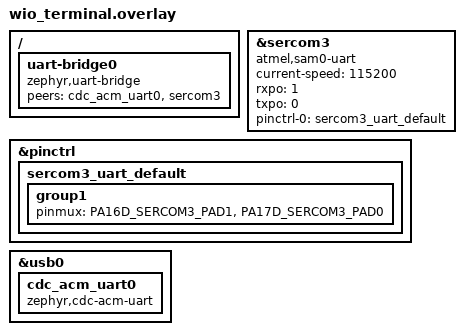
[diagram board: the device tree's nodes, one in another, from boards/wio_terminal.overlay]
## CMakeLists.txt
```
# SPDX-License-Identifier: Apache-2.0

cmake_minimum_required(VERSION 3.20.0)

find_package(Zephyr REQUIRED HINTS $ENV{ZEPHYR_BASE})
project(usb2uart)

include(${ZEPHYR_BASE}/samples/subsys/usb/common/common.cmake)

FILE(GLOB app_sources src/*.c)
target_sources(app PRIVATE ${app_sources})
```

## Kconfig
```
# SPDX-License-Identifier: Apache-2.0

# Source common USB sample options for sample_usbd_init
source "samples/subsys/usb/common/Kconfig.sample_usbd"

config USB2UART_DISPLAY_REFRESH_MS
	int "Display refresh interval in milliseconds"
	default 100
	help
	  How often the LVGL display refreshes status.

source "Kconfig.zephyr"
```

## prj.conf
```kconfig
# Console on board_cdc_acm_uart (kept for USB enumeration)
CONFIG_UART_CONSOLE=y
CONFIG_SHELL=y

# USB Device
CONFIG_USB_DEVICE_STACK_NEXT=y
CONFIG_USBD_CDC_ACM_CLASS=y
CONFIG_CDC_ACM_SERIAL_INITIALIZE_AT_BOOT=n

# Serial / UART
CONFIG_SERIAL=y
CONFIG_UART_INTERRUPT_DRIVEN=y
CONFIG_UART_LINE_CTRL=y
CONFIG_UART_USE_RUNTIME_CONFIGURE=y
CONFIG_UART_BRIDGE=y
CONFIG_UART_BRIDGE_BUF_SIZE=2048

# USB UDC buffers
CONFIG_UDC_BUF_COUNT=32
CONFIG_UDC_BUF_POOL_SIZE=4096

# Sample USBD options
CONFIG_SAMPLE_USBD_PID=0x0001
CONFIG_SAMPLE_USBD_PRODUCT="Wio Terminal USB2UART"

# Logging
CONFIG_LOG=y

# Main stack
CONFIG_MAIN_STACK_SIZE=4096

# Display
CONFIG_DISPLAY=y

# LVGL
CONFIG_LVGL=y
CONFIG_LV_Z_MEM_POOL_SIZE=16384
CONFIG_LV_USE_LABEL=y
CONFIG_LV_FONT_MONTSERRAT_10=y
CONFIG_LV_FONT_MONTSERRAT_14=y
CONFIG_LV_FONT_MONTSERRAT_38=y
CONFIG_LV_Z_VDB_SIZE=10

# Heap for LVGL
CONFIG_HEAP_MEM_POOL_SIZE=8192
```

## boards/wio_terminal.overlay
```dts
/*
 * Wio Terminal USB2UART overlay
 * SERCOM3 -> UART on left Grove (PA17=TX PAD0, PA16=RX PAD1)
 * USB CDC ACM <-> SERCOM3 uart bridge
 *
 * Keep board_cdc_acm_uart (console/shell), add cdc_acm_uart0 for bridge.
 * The device will enumerate as a composite USB device with two CDC ACM interfaces.
 */

/* Override SERCOM3 from I2C to UART */
&sercom3 {
	/delete-property/ compatible;
	/delete-property/ clock-frequency;
	/delete-property/ #address-cells;
	/delete-property/ #size-cells;
	compatible = "atmel,sam0-uart";
	status = "okay";
	current-speed = <115200>;
	rxpo = <1>;
	txpo = <0>;
	pinctrl-0 = <&sercom3_uart_default>;
	pinctrl-names = "default";
};

/* Add SERCOM3 UART pinctrl (PA17=SERCOM3_PAD0 TX, PA16=SERCOM3_PAD1 RX) */
&pinctrl {
	sercom3_uart_default: sercom3_uart_default {
		group1 {
			pinmux = <PA16D_SERCOM3_PAD1>,
				 <PA17D_SERCOM3_PAD0>;
		};
	};
};

/* Second CDC ACM UART instance under USB controller for bridge */
&usb0 {
	cdc_acm_uart0: cdc_acm_uart0 {
		compatible = "zephyr,cdc-acm-uart";
	};
};

/* UART Bridge: CDC ACM <-> SERCOM3 */
/ {
	uart-bridge0 {
		compatible = "zephyr,uart-bridge";
		peers = <&cdc_acm_uart0 &sercom3>;
	};
};
```

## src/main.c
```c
/*
 * SPDX-License-Identifier: Apache-2.0
 */

#include <zephyr/device.h>
#include <zephyr/drivers/uart/uart_bridge.h>
#include <zephyr/kernel.h>
#include <zephyr/usb/usb_device.h>
#include <zephyr/usb/usbd.h>

#include <sample_usbd.h>

#include "bridge_monitor.h"
#include "display.h"

#include <zephyr/logging/log.h>
LOG_MODULE_REGISTER(usb2uart, LOG_LEVEL_INF);

const struct device *const cdc_dev = DEVICE_DT_GET(DT_NODELABEL(cdc_acm_uart0));

static struct usbd_context *sample_usbd;
static bool usb_connected;

#define DEVICE_DT_GET_COMMA(node_id) DEVICE_DT_GET(node_id),

const struct device *uart_bridges[] = {
	DT_FOREACH_STATUS_OKAY(zephyr_uart_bridge, DEVICE_DT_GET_COMMA)
};

static void sample_msg_cb(struct usbd_context *const ctx, const struct usbd_msg *msg)
{
	LOG_INF("USBD message: %s", usbd_msg_type_string(msg->type));

	if (usbd_can_detect_vbus(ctx)) {
		if (msg->type == USBD_MSG_VBUS_READY) {
			usbd_enable(ctx);
		}
		if (msg->type == USBD_MSG_VBUS_REMOVED) {
			usbd_disable(ctx);
		}
	}

	if (msg->type == USBD_MSG_CDC_ACM_LINE_CODING ||
	    msg->type == USBD_MSG_CDC_ACM_CONTROL_LINE_STATE) {
		for (uint8_t i = 0; i < ARRAY_SIZE(uart_bridges); i++) {
			uart_bridge_settings_update(msg->dev, uart_bridges[i]);
		}
	}

	if (msg->type == USBD_MSG_CDC_ACM_CONTROL_LINE_STATE) {
		usb_connected = true;
	}
}

int main(void)
{
	int err;

	sample_usbd = sample_usbd_init_device(sample_msg_cb);
	if (sample_usbd == NULL) {
		LOG_ERR("Failed to initialize USB device");
		return -ENODEV;
	}

	if (!usbd_can_detect_vbus(sample_usbd)) {
		err = usbd_enable(sample_usbd);
		if (err) {
			LOG_ERR("Failed to enable device support");
			return err;
		}
	}

	bridge_monitor_init(cdc_dev, NULL);

	display_init();

	LOG_INF("USB2UART bridge ready");

	while (1) {
		struct uart_config_info cfg;

		bridge_monitor_get_config(&cfg);
		cfg.connected = usb_connected;
		display_update_status(cfg.baudrate, cfg.data_bits,
				     cfg.stop_bits, cfg.parity, cfg.connected);
		display_refresh();
		k_sleep(K_MSEC(CONFIG_USB2UART_DISPLAY_REFRESH_MS));
	}

	return 0;
}
```

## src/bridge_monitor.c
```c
/*
 * SPDX-License-Identifier: Apache-2.0
 */

#include "bridge_monitor.h"
#include <zephyr/drivers/uart.h>
#include <zephyr/logging/log.h>
LOG_MODULE_REGISTER(bridge_monitor, LOG_LEVEL_INF);

static const struct device *cdc_dev;

static struct uart_config_info current_cfg = {
	.baudrate = 115200,
	.data_bits = 8,
	.stop_bits = 1,
	.parity = 0,
	.connected = false,
};

void bridge_monitor_init(const struct device *cdc, const struct device *uart)
{
	ARG_UNUSED(uart);
	cdc_dev = cdc;
}

void bridge_monitor_get_config(struct uart_config_info *cfg)
{
	struct uart_config tmp;
	int ret;

	if (cdc_dev == NULL) {
		*cfg = current_cfg;
		return;
	}

	ret = uart_config_get(cdc_dev, &tmp);
	if (ret == 0) {
		current_cfg.baudrate = tmp.baudrate;
		switch (tmp.data_bits) {
		case UART_CFG_DATA_BITS_5:
			current_cfg.data_bits = 5;
			break;
		case UART_CFG_DATA_BITS_6:
			current_cfg.data_bits = 6;
			break;
		case UART_CFG_DATA_BITS_7:
			current_cfg.data_bits = 7;
			break;
		case UART_CFG_DATA_BITS_8:
			current_cfg.data_bits = 8;
			break;
		case UART_CFG_DATA_BITS_9:
			current_cfg.data_bits = 9;
			break;
		default:
			current_cfg.data_bits = 8;
			break;
		}
		switch (tmp.stop_bits) {
		case UART_CFG_STOP_BITS_0_5:
			current_cfg.stop_bits = 0;
			break;
		case UART_CFG_STOP_BITS_1:
			current_cfg.stop_bits = 1;
			break;
		case UART_CFG_STOP_BITS_1_5:
			current_cfg.stop_bits = 15;
			break;
		case UART_CFG_STOP_BITS_2:
			current_cfg.stop_bits = 2;
			break;
		default:
			current_cfg.stop_bits = 1;
			break;
		}
		switch (tmp.parity) {
		case UART_CFG_PARITY_NONE:
			current_cfg.parity = 0;
			break;
		case UART_CFG_PARITY_ODD:
			current_cfg.parity = 1;
			break;
		case UART_CFG_PARITY_EVEN:
			current_cfg.parity = 2;
			break;
		default:
			current_cfg.parity = 0;
			break;
		}
	}

	*cfg = current_cfg;
}
```

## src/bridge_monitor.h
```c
/*
 * SPDX-License-Identifier: Apache-2.0
 */

#ifndef BRIDGE_MONITOR_H_
#define BRIDGE_MONITOR_H_

#include <zephyr/device.h>
#include <stdint.h>
#include <stdbool.h>

struct uart_config_info {
	uint32_t baudrate;
	uint8_t data_bits;
	uint8_t stop_bits;
	uint8_t parity;
	bool connected;
};

void bridge_monitor_init(const struct device *cdc_dev, const struct device *uart_dev);
void bridge_monitor_get_config(struct uart_config_info *cfg);

#endif /* BRIDGE_MONITOR_H_ */
```

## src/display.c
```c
/*
 * SPDX-License-Identifier: Apache-2.0
 * Nothing Design — monochrome, typographic, subtractive
 */

#include "display.h"
#include <stdio.h>
#include <zephyr/device.h>
#include <zephyr/drivers/display.h>
#include <zephyr/kernel.h>
#include <lvgl.h>

#define SCREEN_W 320
#define SCREEN_H 240

/* Nothing Design color palette */
#define COL_BG         lv_color_black()
#define COL_TEXT       lv_color_white()
#define COL_SECONDARY  lv_color_make(0x99, 0x99, 0x99)
#define COL_DISABLED   lv_color_make(0x55, 0x55, 0x55)
#define COL_ACCENT     lv_color_make(0xD7, 0x19, 0x21) /* Nothing red */
#define COL_CONNECTED  lv_color_make(0x00, 0xE6, 0x76) /* green dot */

/* Wire colors per user spec */
#define COL_WIRE_RX    lv_color_make(0xFF, 0xFF, 0xFF) /* white = RX */
#define COL_WIRE_TX    lv_color_make(0xFF, 0xD6, 0x00) /* yellow = TX */
#define COL_WIRE_VCC   lv_color_make(0xFF, 0x2D, 0x2D) /* red = VCC */
#define COL_WIRE_GND   lv_color_make(0x66, 0x66, 0x66) /* dark gray = GND */

/* Y layout anchors */
#define HERO_Y         32
#define CONFIG_Y       100
#define GROVE_Y        130

/* LVGL objects */
static lv_obj_t *baud_label;     /* hero: baudrate number */
static lv_obj_t *baud_unit;      /* "baud" label */
static lv_obj_t *conn_dot;       /* connection indicator */
static lv_obj_t *config_label;   /* 8N1 config line */
static lv_obj_t *grove_title;    /* "GROVE" label */
static lv_obj_t *wire_labels[4]; /* RX, TX, VCC, GND */
static lv_obj_t *wire_dots[4];   /* colored dots */
static lv_obj_t *usb_label;      /* "USB" at bottom center */

static const char *stop_bits_str(uint8_t sb)
{
	switch (sb) {
	case 0:  return "0.5";
	case 15: return "1.5";
	case 2:  return "2";
	default: return "1";
	}
}

static const char *parity_str(uint8_t p)
{
	switch (p) {
	case 1:  return "O";
	case 2:  return "E";
	default: return "N";
	}
}

void display_init(void)
{
	const struct device *display_dev;
	lv_obj_t *scr;

	display_dev = DEVICE_DT_GET(DT_CHOSEN(zephyr_display));
	if (!device_is_ready(display_dev)) {
		return;
	}

	display_blanking_off(display_dev);
	scr = lv_screen_active();
	lv_obj_set_style_bg_color(scr, COL_BG, LV_PART_MAIN);

	/* ── Primary: Baudrate hero number ── */
	baud_label = lv_label_create(scr);
	lv_label_set_text(baud_label, "---");
	lv_obj_set_style_text_font(baud_label, &lv_font_montserrat_38, LV_PART_MAIN);
	lv_obj_set_style_text_color(baud_label, COL_TEXT, LV_PART_MAIN);
	lv_obj_align(baud_label, LV_ALIGN_TOP_LEFT, 20, HERO_Y);

	/* "baud" unit label — tight to the number */
	baud_unit = lv_label_create(scr);
	lv_label_set_text(baud_unit, "baud");
	lv_obj_set_style_text_font(baud_unit, &lv_font_montserrat_10, LV_PART_MAIN);
	lv_obj_set_style_text_color(baud_unit, COL_SECONDARY, LV_PART_MAIN);
	lv_obj_align_to(baud_unit, baud_label, LV_ALIGN_OUT_BOTTOM_LEFT, 0, 2);

	/* Connection dot — top right, accent when connected */
	conn_dot = lv_obj_create(scr);
	lv_obj_set_size(conn_dot, 10, 10);
	lv_obj_align(conn_dot, LV_ALIGN_TOP_RIGHT, -20, HERO_Y + 6);
	lv_obj_set_style_bg_color(conn_dot, COL_DISABLED, LV_PART_MAIN);
	lv_obj_set_style_border_width(conn_dot, 0, LV_PART_MAIN);
	lv_obj_set_style_radius(conn_dot, 5, LV_PART_MAIN);

	/* ── Secondary: Config line (8N1) ── */
	config_label = lv_label_create(scr);
	lv_label_set_text(config_label, "8 N 1");
	lv_obj_set_style_text_font(config_label, &lv_font_montserrat_14, LV_PART_MAIN);
	lv_obj_set_style_text_color(config_label, COL_SECONDARY, LV_PART_MAIN);
	lv_obj_align(config_label, LV_ALIGN_TOP_LEFT, 20, CONFIG_Y);

	/* ── Tertiary: Grove interface ── */
	grove_title = lv_label_create(scr);
	lv_label_set_text(grove_title, "GROVE  LEFT");
	lv_obj_set_style_text_font(grove_title, &lv_font_montserrat_10, LV_PART_MAIN);
	lv_obj_set_style_text_color(grove_title, COL_DISABLED, LV_PART_MAIN);
	lv_obj_set_style_text_letter_space(grove_title, 2, LV_PART_MAIN);
	lv_obj_align(grove_title, LV_ALIGN_TOP_LEFT, 20, GROVE_Y);

	/* Wire color legend — stacked lines with colored dot + label */
	static const char *wire_names[] = { "RX", "TX", "VCC", "GND" };
	static const char *color_names[] = { "WHITE", "YELLOW", "RED", "BLACK" };
	lv_color_t wc[4];

	wc[0] = COL_WIRE_RX;   /* white */
	wc[1] = COL_WIRE_TX;   /* yellow */
	wc[2] = COL_WIRE_VCC;  /* red */
	wc[3] = COL_WIRE_GND;  /* dark gray */

	for (int i = 0; i < 4; i++) {
		int y_off = GROVE_Y + 20 + i * 16;
		int x = 24;

		/* colored dot */
		wire_dots[i] = lv_obj_create(scr);
		lv_obj_set_size(wire_dots[i], 6, 6);
		lv_obj_align(wire_dots[i], LV_ALIGN_TOP_LEFT, x, y_off + 2);
		lv_obj_set_style_bg_color(wire_dots[i], wc[i], LV_PART_MAIN);
		lv_obj_set_style_border_width(wire_dots[i], 0, LV_PART_MAIN);
		lv_obj_set_style_radius(wire_dots[i], 3, LV_PART_MAIN);

		/* label: "WHITE = RX" */
		char buf[24];

		snprintf(buf, sizeof(buf), "%s = %s", color_names[i], wire_names[i]);

		wire_labels[i] = lv_label_create(scr);
		lv_label_set_text(wire_labels[i], buf);
		lv_obj_set_style_text_font(wire_labels[i], &lv_font_montserrat_10, LV_PART_MAIN);
		lv_obj_set_style_text_color(wire_labels[i], COL_SECONDARY, LV_PART_MAIN);
		lv_obj_align(wire_labels[i], LV_ALIGN_TOP_LEFT, x + 12, y_off);
	}

	/* ── USB interface — bottom center ── */
	usb_label = lv_label_create(scr);
	lv_label_set_text(usb_label, "USB");
	lv_obj_set_style_text_font(usb_label, &lv_font_montserrat_10, LV_PART_MAIN);
	lv_obj_set_style_text_color(usb_label, COL_DISABLED, LV_PART_MAIN);
	lv_obj_set_style_text_letter_space(usb_label, 3, LV_PART_MAIN);
	lv_obj_align(usb_label, LV_ALIGN_BOTTOM_MID, 0, -6);

	/* Horizontal rule above USB */
	lv_obj_t *rule = lv_obj_create(scr);
	lv_obj_set_size(rule, SCREEN_W - 40, 1);
	lv_obj_align(rule, LV_ALIGN_BOTTOM_MID, 0, -22);
	lv_obj_set_style_bg_color(rule, COL_DISABLED, LV_PART_MAIN);
	lv_obj_set_style_border_width(rule, 0, LV_PART_MAIN);
	lv_obj_set_style_radius(rule, 0, LV_PART_MAIN);
}

void display_update_status(uint32_t baudrate, uint8_t data_bits, uint8_t stop_bits,
			   uint8_t parity, bool connected)
{
	char buf[16];

	/* Hero: baudrate number */
	snprintf(buf, sizeof(buf), "%u", baudrate);
	lv_label_set_text(baud_label, buf);

	/* Config line: "8 N 1" */
	snprintf(buf, sizeof(buf), "%u %s %s", data_bits, parity_str(parity), stop_bits_str(stop_bits));
	lv_label_set_text(config_label, buf);

	/* Connection dot */
	lv_obj_set_style_bg_color(conn_dot, connected ? COL_CONNECTED : COL_DISABLED,
				  LV_PART_MAIN);
}

void display_refresh(void)
{
	lv_timer_handler();
}
```

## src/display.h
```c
/*
 * SPDX-License-Identifier: Apache-2.0
 */

#ifndef DISPLAY_H_
#define DISPLAY_H_

#include <stdint.h>
#include <stdbool.h>

void display_init(void);
void display_update_status(uint32_t baudrate, uint8_t data_bits, uint8_t stop_bits,
			   uint8_t parity, bool connected);
void display_refresh(void);

#endif /* DISPLAY_H_ */
```
